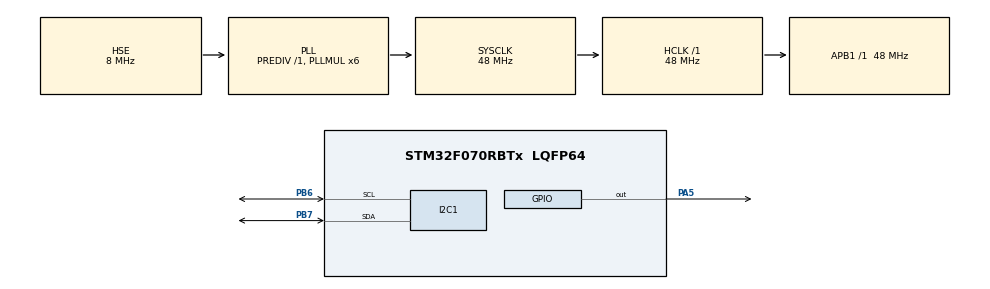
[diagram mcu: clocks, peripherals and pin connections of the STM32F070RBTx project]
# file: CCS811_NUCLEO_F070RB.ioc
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Mcu.Family=STM32F0
Mcu.Name=STM32F070RBTx
Mcu.Package=LQFP64
PA5.Signal=GPIO_Output
PB6.Mode=I2C
PB6.Signal=I2C1_SCL
PB7.Mode=I2C
PB7.Signal=I2C1_SDA
PF0-OSC_IN.Mode=HSE-External-Oscillator
PF0-OSC_IN.Signal=RCC_OSC_IN
PF1-OSC_OUT.Mode=HSE-External-Oscillator
PF1-OSC_OUT.Signal=RCC_OSC_OUT
ProjectManager.HeapSize=0x200
ProjectManager.StackSize=0x400
ProjectManager.TargetToolchain=STM32CubeIDE
RCC.AHBFreq_Value=48000000
RCC.APB1Freq_Value=48000000
RCC.APB1TimFreq_Value=48000000
RCC.HCLKFreq_Value=48000000
RCC.PLLMUL=RCC_PLL_MUL6
RCC.PLLSourceVirtual=RCC_PLLSOURCE_HSE
RCC.SYSCLKFreq_VALUE=48000000
RCC.SYSCLKSource=RCC_SYSCLKSOURCE_PLLCLK
board=NUCLEO-F070RB

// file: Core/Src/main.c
/* USER CODE BEGIN Header */
/**
  ******************************************************************************
  * @file           : main.c
  * @brief          : Main program body
  ******************************************************************************
  * @attention
  *
  * <h2><center>&copy; Copyright (c) 2021 STMicroelectronics.
  * All rights reserved.</center></h2>
  *
  * This software component is licensed by ST under BSD 3-Clause license,
  * the "License"; You may not use this file except in compliance with the
  * License. You may obtain a copy of the License at:
  *                        opensource.org/licenses/BSD-3-Clause
  *
  ******************************************************************************
  */
/* USER CODE END Header */
#include "main.h"
#include "i2c.h"
#include "gpio.h"

/* USER CODE BEGIN Includes */
#include "CCS811.h"
/* USER CODE END Includes */

void SystemClock_Config(void);

/* USER CODE BEGIN 0 */
uint16_t CO2 = 0;
uint16_t TVOC = 0;
/* USER CODE END 0 */

int main(void)
{

  /* MCU Configuration--------------------------------------------------------*/

  /* Reset of all peripherals, Initializes the Flash interface and the Systick. */
  HAL_Init();

  /* Configure the system clock */
  SystemClock_Config();

  /* Initialize all configured peripherals */
  MX_GPIO_Init();
  MX_I2C1_Init();
  /* USER CODE BEGIN 2 */
  HAL_GPIO_WritePin(GPIOA, GPIO_PIN_5, GPIO_PIN_RESET);
  CCS822_Init(1);
  /* USER CODE END 2 */

  /* Infinite loop */
  /* USER CODE BEGIN WHILE */
  while (1)
  {
	  CCS811_ReadData();

	  CO2 = (CCS811_AlgorithmResults._eCO2_HighByte << 8) | (CCS811_AlgorithmResults._eCO2_LowByte);
	  TVOC = (CCS811_AlgorithmResults._eTVOC_HighByte << 8) | (CCS811_AlgorithmResults._eTVOC_LowByte);

	  CCS811_IdleMode();
	  HAL_Delay(2000);
	  CCS811_WakeUp(1);
    /* USER CODE END WHILE */

  }
}

void SystemClock_Config(void)
{
  RCC_OscInitTypeDef RCC_OscInitStruct = {0};
  RCC_ClkInitTypeDef RCC_ClkInitStruct = {0};
  RCC_PeriphCLKInitTypeDef PeriphClkInit = {0};

  /** Initializes the RCC Oscillators according to the specified parameters
  * in the RCC_OscInitTypeDef structure.
  */
  RCC_OscInitStruct.OscillatorType = RCC_OSCILLATORTYPE_HSI|RCC_OSCILLATORTYPE_HSE;
  RCC_OscInitStruct.HSEState = RCC_HSE_ON;
  RCC_OscInitStruct.HSIState = RCC_HSI_ON;
  RCC_OscInitStruct.HSICalibrationValue = RCC_HSICALIBRATION_DEFAULT;
  RCC_OscInitStruct.PLL.PLLState = RCC_PLL_ON;
  RCC_OscInitStruct.PLL.PLLSource = RCC_PLLSOURCE_HSE;
  RCC_OscInitStruct.PLL.PLLMUL = RCC_PLL_MUL6;
  RCC_OscInitStruct.PLL.PREDIV = RCC_PREDIV_DIV1;
  if (HAL_RCC_OscConfig(&RCC_OscInitStruct) != HAL_OK)
  {
    Error_Handler();
  }
  /** Initializes the CPU, AHB and APB buses clocks
  */
  RCC_ClkInitStruct.ClockType = RCC_CLOCKTYPE_HCLK|RCC_CLOCKTYPE_SYSCLK
                              |RCC_CLOCKTYPE_PCLK1;
  RCC_ClkInitStruct.SYSCLKSource = RCC_SYSCLKSOURCE_PLLCLK;
  RCC_ClkInitStruct.AHBCLKDivider = RCC_SYSCLK_DIV1;
  RCC_ClkInitStruct.APB1CLKDivider = RCC_HCLK_DIV1;

  if (HAL_RCC_ClockConfig(&RCC_ClkInitStruct, FLASH_LATENCY_1) != HAL_OK)
  {
    Error_Handler();
  }
  PeriphClkInit.PeriphClockSelection = RCC_PERIPHCLK_I2C1;
  PeriphClkInit.I2c1ClockSelection = RCC_I2C1CLKSOURCE_HSI;
  if (HAL_RCCEx_PeriphCLKConfig(&PeriphClkInit) != HAL_OK)
  {
    Error_Handler();
  }
}

void Error_Handler(void)
{
}

/************************ (C) COPYRIGHT STMicroelectronics *****END OF FILE****/
